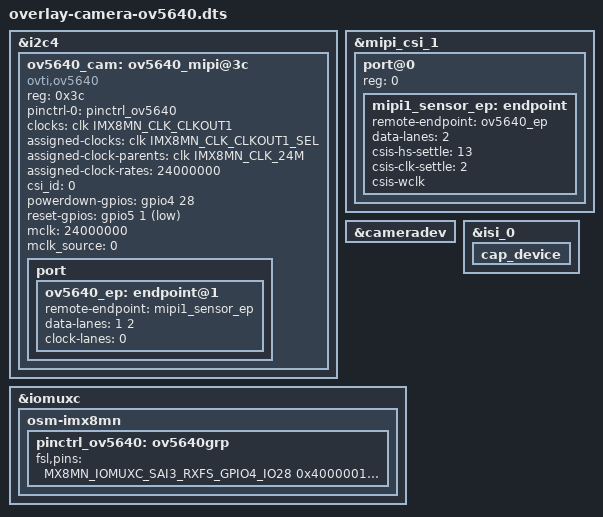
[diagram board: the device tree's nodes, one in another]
/*
 * Copyright (C) 2021 AVNET Integrated, MSC Technologies GmbH
 *
 * This program is free software; you can redistribute it and/or
 * modify it under the terms of the GNU General Public License as
 * published by the Free Software Foundation version 2.
 *
 * This program is distributed "as is" WITHOUT ANY WARRANTY of any
 * kind, whether express or implied; without even the implied warranty
 * of MERCHANTABILITY or FITNESS FOR A PARTICULAR PURPOSE.  See the
 * GNU General Public License for more details.
 */

/dts-v1/;
/plugin/;

#include <dt-bindings/clock/imx8mn-clock.h>
#include <dt-bindings/gpio/gpio.h>
#include "../../freescale/imx8mn-pinfunc.h"

/ {
	fragment@9000 {
		target = <&i2c4>;
		__overlay__ {
			#address-cells = <1>;
			#size-cells = <0>;
			ov5640_cam: ov5640_mipi@3c {
				compatible = "ovti,ov5640";
				reg = <0x3c>;
				pinctrl-names = "default";
				pinctrl-0 = <&pinctrl_ov5640>;
				clocks = <&clk IMX8MN_CLK_CLKOUT1>;
				clock-names = "xclk";
				assigned-clocks = <&clk IMX8MN_CLK_CLKOUT1_SEL>;
				assigned-clock-parents = <&clk IMX8MN_CLK_24M>;
				assigned-clock-rates = <24000000>;
				csi_id = <0>;
				powerdown-gpios = <&gpio4 28 GPIO_ACTIVE_HIGH>;
				reset-gpios     = <&gpio5  1 GPIO_ACTIVE_LOW>;
				mclk = <24000000>;
				mclk_source = <0>;
				status = "okay";
				port {
					ov5640_ep: endpoint@1 {
						remote-endpoint = <&mipi1_sensor_ep>;
						data-lanes = <1 2>;
						clock-lanes = <0>;

					};
				};

			};
		};
	};

	fragment@9001 {
		target = <&mipi_csi_1>;
		__overlay__ {
			#address-cells = <1>;
			#size-cells = <0>;
			status = "okay";
			port@0 {
				reg= <0>;
				mipi1_sensor_ep: endpoint {
					remote-endpoint = <&ov5640_ep>;
					data-lanes = <2>;
					csis-hs-settle = <13>;
					csis-clk-settle = <2>;
					csis-wclk;
				};
			};
		};
	};

	fragment@9002 {
		target = <&cameradev>;
		__overlay__ {
			status = "okay";
		};
	};

	fragment@9003 {
		target = <&isi_0>;
		__overlay__ {
			status = "okay";
			cap_device {
				status = "okay";
			};
		};
	};

	fragment@9004 {
		target = <&iomuxc>;
		__overlay__ {
		        osm-imx8mn {
				pinctrl_ov5640: ov5640grp {
					fsl,pins = <
						MX8MN_IOMUXC_SAI3_RXFS_GPIO4_IO28	0x40000019	/* CAM_PWR  */
						MX8MN_IOMUXC_SAI3_TXD_GPIO5_IO1		0x40000019	/* CAM_RST# */
					>;
				};
			};
		};
	};
};
